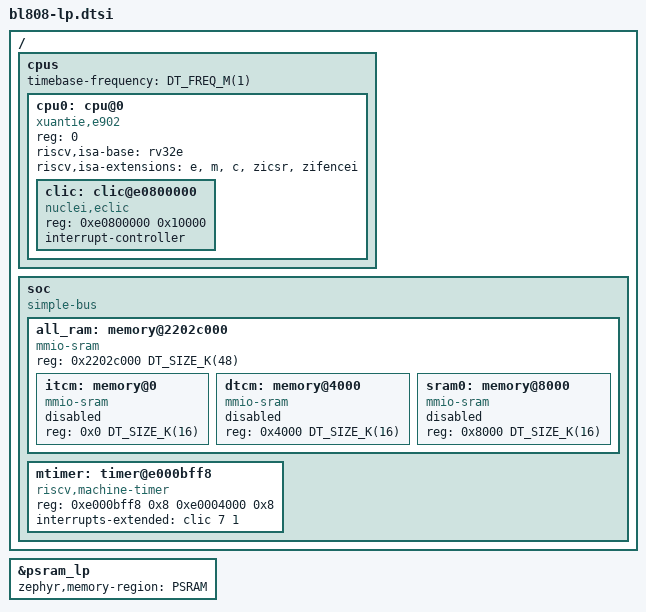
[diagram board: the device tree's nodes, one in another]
/*
 * Copyright (c) 2026 MASSDRIVER EI (massdriver.space)
 *
 * SPDX-License-Identifier: Apache-2.0
 *
 */

#include <bflb/bl808_32bit_common.dtsi>

/ {
	#address-cells = <1>;
	#size-cells = <1>;

	cpus {
		#address-cells = <1>;
		#size-cells = <0>;
		timebase-frequency = <DT_FREQ_M(1)>;

		cpu0: cpu@0 {
			device_type = "cpu";
			compatible = "xuantie,e902", "riscv";
			reg = <0>;
			riscv,isa-base = "rv32e";
			riscv,isa-extensions = "e", "m", "c", "zicsr", "zifencei";
			status = "okay";

			#address-cells = <1>;
			#size-cells = <1>;

			clic: clic@e0800000 {
				compatible = "nuclei,eclic";
				reg = <0xe0800000 0x10000>;
				#address-cells = <0>;
				#interrupt-cells = <2>;
				interrupt-controller;
			};
		};
	};

	soc {
		compatible = "simple-bus";
		#address-cells = <1>;
		#size-cells = <1>;
		ranges;

		/* LP has its own not-shared memory overlapping in the same area as M0's */
		all_ram: memory@2202c000 {
			compatible = "mmio-sram";
			reg = <0x2202c000 DT_SIZE_K(48)>;
			#address-cells = <1>;
			#size-cells = <1>;
			ranges = <0x0 0x2202c000 DT_SIZE_K(48)>;

			itcm: memory@0 {
				compatible = "mmio-sram";
				reg = <0x0 DT_SIZE_K(16)>;
				#address-cells = <1>;
				#size-cells = <1>;
				ranges = <0x0 0x0 DT_SIZE_K(16)>;
				status = "disabled";
			};

			dtcm: memory@4000 {
				compatible = "mmio-sram";
				reg = <0x4000 DT_SIZE_K(16)>;
				#address-cells = <1>;
				#size-cells = <1>;
				ranges = <0x0 0x4000 DT_SIZE_K(16)>;
				status = "disabled";
			};

			sram0: memory@8000 {
				compatible = "mmio-sram";
				reg = <0x8000 DT_SIZE_K(16)>;
				#address-cells = <1>;
				#size-cells = <1>;
				ranges = <0x0 0x8000 DT_SIZE_K(16)>;
				status = "disabled";
			};
		};

		mtimer: timer@e000bff8 {
			compatible = "riscv,machine-timer";
			reg = <0xe000bff8 0x8 0xe0004000 0x8>;
			reg-names = "mtime", "mtimecmp";

			interrupts-extended = <&clic 7 1>;
		};
	};
};

psram: &psram_lp {
	status = "okay";
	zephyr,memory-region = "PSRAM";
};
